# rCSL_afifo_001 register map
Vendor: Texas Instruments
Peripheral module from a debugger description file (folder OMAPL138_C6748).
Registers are 32-bit, access not given, reset 0x1604 unless marked. A register's access mark holds for its fields unless they carry their own. Offsets are as the file gives them; lines under a group give offsets from that group; [hi:lo] are bit positions; {n}, {i} and the like mark numbered series; 'fields as' and 'values as' point back to an identical list; <NAME> marks a mode.

## AFIFO — FIFO for McASP
0x00 REVID ro reset 0x44311100 — Peripheral identification register
  [31:0] REV
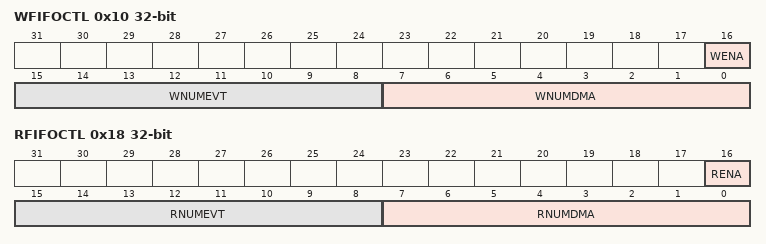
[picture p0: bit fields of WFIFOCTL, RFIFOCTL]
0x10 WFIFOCTL — Write FIFO control
  [16] WENA rw — Write FIFO enable
    0=DISABLED; 1=ENABLED
  [15:8] WNUMEVT rw — Write word count to generate TX evt to host.
    0=0WORDS; 4=4WORDS; 8=8WORDS; 18=12WORDS; 22=16WORDS; 32=20WORDS; 36=24WORDS; 40=28WORDS; 50=32WORDS; 54=36WORDS; 64=40WORDS; 68=44WORDS; 72=48WORDS; 82=52WORDS; 86=56WORDS; 96=60WORDS; 100=64WORDS
  [7:0] WNUMDMA rw — Write word count.
    {v}={v}WORDS (v=0..9); {v}={v-6}WORDS (v=16..22)
0x14 WFIFOSTS reset 0x0 — Write FIFO status
  [7:0] WLVL ro — Write level. Num of 32-bit words currently in FIFO.
0x18 RFIFOCTL — Read FIFO control
  [16] RENA rw — Read FIFO enable
    0=DISABLED; 1=ENABLED
  [15:8] RNUMEVT rw — Read word count to generate RX evt to host.
    values as WFIFOCTL.WNUMEVT
  [7:0] RNUMDMA rw — Read word count.
    {v}={v}WORDS (v=0..9); {v}={v-6}WORDS (v=16..22)
0x1C RFIFOSTS reset 0x0 — Read FIFO status
  [7:0] RLVL ro — Read level. Num of 32-bit words currently in FIFO.
